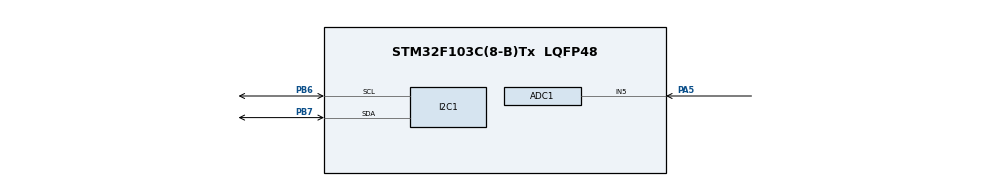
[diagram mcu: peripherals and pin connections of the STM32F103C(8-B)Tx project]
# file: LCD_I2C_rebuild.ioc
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ADC1.Channel-0\#ChannelRegularConversion=ADC_CHANNEL_5
ADC1.ContinuousConvMode=ENABLE
ADC1.NbrOfConversionFlag=1
ADC1.Rank-0\#ChannelRegularConversion=1
ADC1.SamplingTime-0\#ChannelRegularConversion=ADC_SAMPLETIME_1CYCLE_5
ADC1.master=1
Mcu.Family=STM32F1
Mcu.Name=STM32F103C(8-B)Tx
Mcu.Package=LQFP48
NVIC.ADC1_2_IRQn=true\:1\:0\:true\:false\:true\:true\:true\:true
NVIC.PriorityGroup=NVIC_PRIORITYGROUP_4
PA13.Mode=Serial_Wire
PA13.Signal=SYS_JTMS-SWDIO
PA14.Mode=Serial_Wire
PA14.Signal=SYS_JTCK-SWCLK
PA5.Signal=ADCx_IN5
PB6.Mode=I2C
PB6.Signal=I2C1_SCL
PB7.Mode=I2C
PB7.Signal=I2C1_SDA
PC14-OSC32_IN.Mode=LSE-External-Oscillator
PC14-OSC32_IN.Signal=RCC_OSC32_IN
PC15-OSC32_OUT.Mode=LSE-External-Oscillator
PC15-OSC32_OUT.Signal=RCC_OSC32_OUT
ProjectManager.HeapSize=0x200
ProjectManager.StackSize=0x400
ProjectManager.TargetToolchain=MDK-ARM V5.32
RCC.APB1Freq_Value=8000000
RCC.APB2Freq_Value=8000000
SH.ADCx_IN5.0=ADC1_IN5,IN5
board=custom

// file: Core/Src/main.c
/* USER CODE BEGIN Header */
/**
  ******************************************************************************
  * @file           : main.c
  * @brief          : Main program body
  ******************************************************************************
  * @attention
  *
  * Copyright (c) 2024 STMicroelectronics.
  * All rights reserved.
  *
  * This software is licensed under terms that can be found in the LICENSE file
  * in the root directory of this software component.
  * If no LICENSE file comes with this software, it is provided AS-IS.
  *
  ******************************************************************************
  */
/* USER CODE END Header */
#include "main.h"

/* USER CODE BEGIN Includes */
#include <stdio.h>
#include <lcd_16x2.h>

/* USER CODE END Includes */

/* USER CODE BEGIN PD */
uint32_t result;
float	volt;
char convert[5];
/* USER CODE END PD */

ADC_HandleTypeDef hadc1;

I2C_HandleTypeDef hi2c1;

void SystemClock_Config(void);
static void MX_GPIO_Init(void);
static void MX_ADC1_Init(void);
static void MX_I2C1_Init(void);

int main(void)
{

  /* MCU Configuration--------------------------------------------------------*/

  /* Reset of all peripherals, Initializes the Flash interface and the Systick. */
  HAL_Init();

  /* USER CODE BEGIN Init */
	Lcd_Init();
  /* USER CODE END Init */

  /* Configure the system clock */
  SystemClock_Config();

  /* Initialize all configured peripherals */
  MX_GPIO_Init();
  MX_ADC1_Init();
  MX_I2C1_Init();
  /* USER CODE BEGIN 2 */
	Lcd_gotoxy(0,0);
	Lcd_write_string("Volt: ");
	Lcd_gotoxy(11,0);
	Lcd_write_string("Vv");
	Lcd_gotoxy(0,1);
	Lcd_write_string("ADC;  ");
  /* USER CODE END 2 */

  /* Infinite loop */
  while (1)
  {

    /* USER CODE BEGIN 3 */
		HAL_Delay(10);
		Lcd_gotoxy(6,0);
		Lcd_write_string(convert);
		Lcd_gotoxy(4,1);
		Lcd_write_int(result);
  }
  /* USER CODE END 3 */
}

void SystemClock_Config(void)
{
  RCC_OscInitTypeDef RCC_OscInitStruct = {0};
  RCC_ClkInitTypeDef RCC_ClkInitStruct = {0};
  RCC_PeriphCLKInitTypeDef PeriphClkInit = {0};

  /** Initializes the RCC Oscillators according to the specified parameters
  * in the RCC_OscInitTypeDef structure.
  */
  RCC_OscInitStruct.OscillatorType = RCC_OSCILLATORTYPE_HSI;
  RCC_OscInitStruct.HSIState = RCC_HSI_ON;
  RCC_OscInitStruct.HSICalibrationValue = RCC_HSICALIBRATION_DEFAULT;
  RCC_OscInitStruct.PLL.PLLState = RCC_PLL_NONE;
  if (HAL_RCC_OscConfig(&RCC_OscInitStruct) != HAL_OK)
  {
    Error_Handler();
  }

  /** Initializes the CPU, AHB and APB buses clocks
  */
  RCC_ClkInitStruct.ClockType = RCC_CLOCKTYPE_HCLK|RCC_CLOCKTYPE_SYSCLK
                              |RCC_CLOCKTYPE_PCLK1|RCC_CLOCKTYPE_PCLK2;
  RCC_ClkInitStruct.SYSCLKSource = RCC_SYSCLKSOURCE_HSI;
  RCC_ClkInitStruct.AHBCLKDivider = RCC_SYSCLK_DIV1;
  RCC_ClkInitStruct.APB1CLKDivider = RCC_HCLK_DIV1;
  RCC_ClkInitStruct.APB2CLKDivider = RCC_HCLK_DIV1;

  if (HAL_RCC_ClockConfig(&RCC_ClkInitStruct, FLASH_LATENCY_0) != HAL_OK)
  {
    Error_Handler();
  }
  PeriphClkInit.PeriphClockSelection = RCC_PERIPHCLK_ADC;
  PeriphClkInit.AdcClockSelection = RCC_ADCPCLK2_DIV2;
  if (HAL_RCCEx_PeriphCLKConfig(&PeriphClkInit) != HAL_OK)
  {
    Error_Handler();
  }
}

static void MX_ADC1_Init(void)
{

  ADC_ChannelConfTypeDef sConfig = {0};

  /** Common config
  */
  hadc1.Instance = ADC1;
  hadc1.Init.ScanConvMode = ADC_SCAN_DISABLE;
  hadc1.Init.ContinuousConvMode = ENABLE;
  hadc1.Init.DiscontinuousConvMode = DISABLE;
  hadc1.Init.ExternalTrigConv = ADC_SOFTWARE_START;
  hadc1.Init.DataAlign = ADC_DATAALIGN_RIGHT;
  hadc1.Init.NbrOfConversion = 1;
  if (HAL_ADC_Init(&hadc1) != HAL_OK)
  {
    Error_Handler();
  }

  /** Configure Regular Channel
  */
  sConfig.Channel = ADC_CHANNEL_5;
  sConfig.Rank = ADC_REGULAR_RANK_1;
  sConfig.SamplingTime = ADC_SAMPLETIME_1CYCLE_5;
  if (HAL_ADC_ConfigChannel(&hadc1, &sConfig) != HAL_OK)
  {
    Error_Handler();
  }

}

static void MX_I2C1_Init(void)
{

  hi2c1.Instance = I2C1;
  hi2c1.Init.ClockSpeed = 100000;
  hi2c1.Init.DutyCycle = I2C_DUTYCYCLE_2;
  hi2c1.Init.OwnAddress1 = 0;
  hi2c1.Init.AddressingMode = I2C_ADDRESSINGMODE_7BIT;
  hi2c1.Init.DualAddressMode = I2C_DUALADDRESS_DISABLE;
  hi2c1.Init.OwnAddress2 = 0;
  hi2c1.Init.GeneralCallMode = I2C_GENERALCALL_DISABLE;
  hi2c1.Init.NoStretchMode = I2C_NOSTRETCH_DISABLE;
  if (HAL_I2C_Init(&hi2c1) != HAL_OK)
  {
    Error_Handler();
  }

}

static void MX_GPIO_Init(void)
{

  /* GPIO Ports Clock Enable */
  __HAL_RCC_GPIOC_CLK_ENABLE();
  __HAL_RCC_GPIOA_CLK_ENABLE();
  __HAL_RCC_GPIOB_CLK_ENABLE();

}

/* USER CODE BEGIN 4 */
void HAL_ADC_ConvCpltCallback(ADC_HandleTypeDef* hadc){
		if(hadc ->Instance == hadc1.Instance){
			result = HAL_ADC_GetValue(&hadc1);
			volt = (result*3.3)/3450;
			sprintf(convert, "%.2f", volt);
		}
}
/* USER CODE END 4 */

void Error_Handler(void)
{
  __disable_irq();
  while (1)
  {
  }
}
